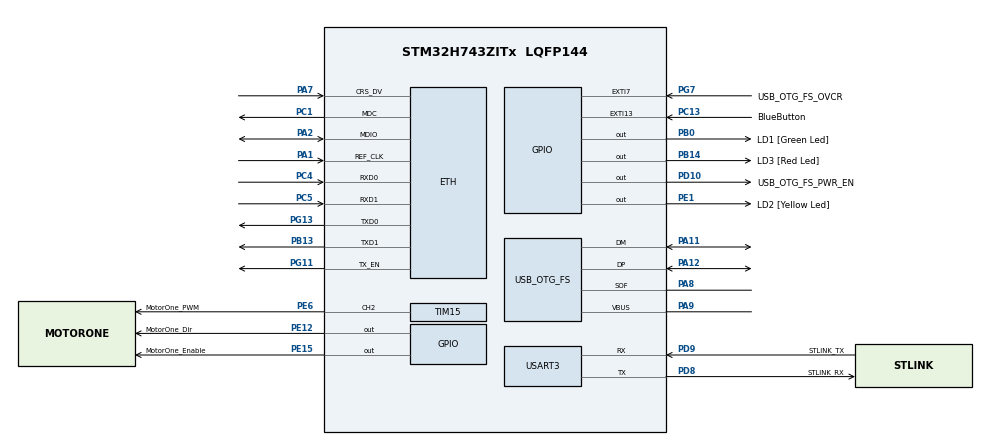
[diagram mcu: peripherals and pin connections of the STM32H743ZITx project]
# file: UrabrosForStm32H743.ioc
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Dma.Request0=USART3_RX
Dma.Request1=USART3_TX
Dma.USART3_RX.0.Direction=DMA_PERIPH_TO_MEMORY
Dma.USART3_RX.0.EventEnable=DISABLE
Dma.USART3_RX.0.FIFOMode=DMA_FIFOMODE_DISABLE
Dma.USART3_RX.0.Instance=DMA1_Stream0
Dma.USART3_RX.0.MemDataAlignment=DMA_MDATAALIGN_BYTE
Dma.USART3_RX.0.MemInc=DMA_MINC_ENABLE
Dma.USART3_RX.0.Mode=DMA_CIRCULAR
Dma.USART3_RX.0.PeriphDataAlignment=DMA_PDATAALIGN_BYTE
Dma.USART3_RX.0.PeriphInc=DMA_PINC_DISABLE
Dma.USART3_RX.0.Polarity=HAL_DMAMUX_REQ_GEN_RISING
Dma.USART3_RX.0.Priority=DMA_PRIORITY_LOW
Dma.USART3_RX.0.RequestNumber=1
Dma.USART3_RX.0.SignalID=NONE
Dma.USART3_RX.0.SyncEnable=DISABLE
Dma.USART3_RX.0.SyncPolarity=HAL_DMAMUX_SYNC_NO_EVENT
Dma.USART3_RX.0.SyncRequestNumber=1
Dma.USART3_RX.0.SyncSignalID=NONE
Dma.USART3_TX.1.Direction=DMA_MEMORY_TO_PERIPH
Dma.USART3_TX.1.EventEnable=DISABLE
Dma.USART3_TX.1.FIFOMode=DMA_FIFOMODE_DISABLE
Dma.USART3_TX.1.Instance=DMA1_Stream1
Dma.USART3_TX.1.MemDataAlignment=DMA_MDATAALIGN_BYTE
Dma.USART3_TX.1.MemInc=DMA_MINC_ENABLE
Dma.USART3_TX.1.Mode=DMA_NORMAL
Dma.USART3_TX.1.PeriphDataAlignment=DMA_PDATAALIGN_BYTE
Dma.USART3_TX.1.PeriphInc=DMA_PINC_DISABLE
Dma.USART3_TX.1.Polarity=HAL_DMAMUX_REQ_GEN_RISING
Dma.USART3_TX.1.Priority=DMA_PRIORITY_LOW
Dma.USART3_TX.1.RequestNumber=1
Dma.USART3_TX.1.SignalID=NONE
Dma.USART3_TX.1.SyncEnable=DISABLE
Dma.USART3_TX.1.SyncPolarity=HAL_DMAMUX_SYNC_NO_EVENT
Dma.USART3_TX.1.SyncRequestNumber=1
Dma.USART3_TX.1.SyncSignalID=NONE
ETH.MediaInterface=HAL_ETH_RMII_MODE
FREERTOS.Tasks01=defaultTask,0,128,StartDefaultTask,Default,NULL,Dynamic,NULL,NULL
Mcu.Family=STM32H7
Mcu.Name=STM32H743ZITx
Mcu.Package=LQFP144
NVIC.DMA1_Stream0_IRQn=true\:5\:0\:false\:false\:true\:true\:false\:true
NVIC.DMA1_Stream1_IRQn=true\:5\:0\:false\:false\:true\:true\:false\:true
NVIC.EXTI15_10_IRQn=true\:5\:0\:false\:false\:true\:true\:true\:true
NVIC.PriorityGroup=NVIC_PRIORITYGROUP_4
NVIC.TIM15_IRQn=true\:5\:0\:false\:false\:true\:true\:true\:true
NVIC.TIM7_IRQn=true\:0\:0\:false\:false\:true\:false\:false\:true
NVIC.TimeBase=TIM7_IRQn
NVIC.TimeBaseIP=TIM7
NVIC.USART3_IRQn=true\:5\:0\:false\:false\:true\:true\:true\:true
PA1.Mode=RMII
PA1.Signal=ETH_REF_CLK
PA11.Mode=Device_Only
PA11.Signal=USB_OTG_FS_DM
PA12.Mode=Device_Only
PA12.Signal=USB_OTG_FS_DP
PA2.Mode=RMII
PA2.Signal=ETH_MDIO
PA7.Mode=RMII
PA7.Signal=ETH_CRS_DV
PA8.Mode=Activate_SOF_FS
PA8.Signal=USB_OTG_FS_SOF
PA9.Mode=Activate_VBUS
PA9.Signal=USB_OTG_FS_VBUS
PB0.GPIO_Label=LD1 [Green Led]
PB0.Signal=GPIO_Output
PB13.Mode=RMII
PB13.Signal=ETH_TXD1
PB14.GPIO_Label=LD3 [Red Led]
PB14.Signal=GPIO_Output
PC1.Mode=RMII
PC1.Signal=ETH_MDC
PC13.GPIO_Label=BlueButton
PC13.Signal=GPXTI13
PC14-OSC32_IN\ (OSC32_IN).Mode=LSE-External-Oscillator
PC14-OSC32_IN\ (OSC32_IN).Signal=RCC_OSC32_IN
PC15-OSC32_OUT\ (OSC32_OUT).Mode=LSE-External-Oscillator
PC15-OSC32_OUT\ (OSC32_OUT).Signal=RCC_OSC32_OUT
PC4.Mode=RMII
PC4.Signal=ETH_RXD0
PC5.Mode=RMII
PC5.Signal=ETH_RXD1
PD10.GPIO_Label=USB_OTG_FS_PWR_EN
PD10.Signal=GPIO_Output
PD8.GPIO_Label=STLINK_RX
PD8.Mode=Asynchronous
PD8.Signal=USART3_TX
PD9.GPIO_Label=STLINK_TX
PD9.Mode=Asynchronous
PD9.Signal=USART3_RX
PE1.GPIO_Label=LD2 [Yellow Led]
PE1.Signal=GPIO_Output
PE12.GPIO_Label=MotorOne_Dir
PE12.Signal=GPIO_Output
PE15.GPIO_Label=MotorOne_Enable
PE15.Signal=GPIO_Output
PE6.GPIO_Label=MotorOne_PWM
PE6.Signal=S_TIM15_CH2
PG11.Mode=RMII
PG11.Signal=ETH_TX_EN
PG13.Mode=RMII
PG13.Signal=ETH_TXD0
PG7.GPIO_Label=USB_OTG_FS_OVCR
PG7.Signal=GPXTI7
PH0-OSC_IN\ (PH0).Mode=HSE-External-Clock-Source
PH0-OSC_IN\ (PH0).Signal=RCC_OSC_IN
PH1-OSC_OUT\ (PH1).Signal=RCC_OSC_OUT
ProjectManager.HeapSize=0x200
ProjectManager.StackSize=0x400
ProjectManager.TargetToolchain=STM32CubeIDE
RCC.ADCFreq_Value=16125000
RCC.APB1Freq_Value=64000000
RCC.APB2Freq_Value=64000000
RCC.APB3Freq_Value=64000000
RCC.APB4Freq_Value=64000000
RCC.CortexFreq_Value=64000000
RCC.DIVM1=1
RCC.DIVN1=24
RCC.DIVQ1=4
RCC.HCLKFreq_Value=64000000
RCC.HSE_VALUE=8000000
RCC.PLL2FRACN=0
RCC.PLL3FRACN=0
RCC.PLLFRACN=0
RCC.SYSCLKFreq_VALUE=64000000
RCC.Tim1Mul=1
RCC.Tim2Mul=1
RCC.USBFreq_Value=48000000
SH.S_TIM15_CH2.0=TIM15_CH2,PWM Generation2 CH2
TIM15.Channel-PWM\ Generation2\ CH2=TIM_CHANNEL_2
USART3.VirtualMode-Asynchronous=VM_ASYNC
USB_OTG_FS.VirtualMode=Device_Only
VP_FREERTOS_VS_CMSIS_V1.Mode=CMSIS_V1
VP_SYS_VS_tim7.Mode=TIM7
board=NUCLEO-H743ZI2

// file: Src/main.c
/* USER CODE BEGIN Header */
/**
  ******************************************************************************
  * @file           : main.c
  * @brief          : Main program body
  ******************************************************************************
  * @attention
  *
  * <h2><center>&copy; Copyright (c) 2020 STMicroelectronics.
  * All rights reserved.</center></h2>
  *
  * This software component is licensed by ST under Ultimate Liberty license
  * SLA0044, the "License"; You may not use this file except in compliance with
  * the License. You may obtain a copy of the License at:
  *                             www.st.com/SLA0044
  *
  ******************************************************************************
  */
/* USER CODE END Header */
#include "main.h"
#include "cmsis_os.h"
#include "dma.h"
#include "eth.h"
#include "tim.h"
#include "usart.h"
#include "usb_otg.h"
#include "gpio.h"
#include "UrabrosMaster.h"

void SystemClock_Config(void);

int main(void)
{

  /* MCU Configuration--------------------------------------------------------*/

  /* Reset of all peripherals, Initializes the Flash interface and the Systick. */
  HAL_Init();

  /* Configure the system clock */
  SystemClock_Config();

  /* Initialize all configured peripherals */
  MX_GPIO_Init();
  MX_DMA_Init();
  MX_ETH_Init();
  MX_USART3_UART_Init();
  MX_USB_OTG_FS_PCD_Init();
  MX_TIM15_Init();
  /* USER CODE BEGIN 2 */
  UrabrosInit();
  /* USER CODE END 2 */

  /* Call init function for freertos objects (in freertos.c) */
  /* Start scheduler */
  osKernelStart();

  /* We should never get here as control is now taken by the scheduler */
  /* Infinite loop */
  while (1)
  {

  }
}

void SystemClock_Config(void)
{
  RCC_OscInitTypeDef RCC_OscInitStruct = {0};
  RCC_ClkInitTypeDef RCC_ClkInitStruct = {0};
  RCC_PeriphCLKInitTypeDef PeriphClkInitStruct = {0};

  /** Supply configuration update enable
  */
  HAL_PWREx_ConfigSupply(PWR_LDO_SUPPLY);
  /** Configure the main internal regulator output voltage
  */
  __HAL_PWR_VOLTAGESCALING_CONFIG(PWR_REGULATOR_VOLTAGE_SCALE3);

  while(!__HAL_PWR_GET_FLAG(PWR_FLAG_VOSRDY)) {}
  /** Initializes the RCC Oscillators according to the specified parameters
  * in the RCC_OscInitTypeDef structure.
  */
  RCC_OscInitStruct.OscillatorType = RCC_OSCILLATORTYPE_HSI|RCC_OSCILLATORTYPE_HSE;
  RCC_OscInitStruct.HSEState = RCC_HSE_BYPASS;
  RCC_OscInitStruct.HSIState = RCC_HSI_DIV1;
  RCC_OscInitStruct.HSICalibrationValue = RCC_HSICALIBRATION_DEFAULT;
  RCC_OscInitStruct.PLL.PLLState = RCC_PLL_ON;
  RCC_OscInitStruct.PLL.PLLSource = RCC_PLLSOURCE_HSE;
  RCC_OscInitStruct.PLL.PLLM = 1;
  RCC_OscInitStruct.PLL.PLLN = 24;
  RCC_OscInitStruct.PLL.PLLP = 2;
  RCC_OscInitStruct.PLL.PLLQ = 4;
  RCC_OscInitStruct.PLL.PLLR = 2;
  RCC_OscInitStruct.PLL.PLLRGE = RCC_PLL1VCIRANGE_3;
  RCC_OscInitStruct.PLL.PLLVCOSEL = RCC_PLL1VCOWIDE;
  RCC_OscInitStruct.PLL.PLLFRACN = 0;
  if (HAL_RCC_OscConfig(&RCC_OscInitStruct) != HAL_OK)
  {
    Error_Handler();
  }
  /** Initializes the CPU, AHB and APB buses clocks
  */
  RCC_ClkInitStruct.ClockType = RCC_CLOCKTYPE_HCLK|RCC_CLOCKTYPE_SYSCLK
                              |RCC_CLOCKTYPE_PCLK1|RCC_CLOCKTYPE_PCLK2
                              |RCC_CLOCKTYPE_D3PCLK1|RCC_CLOCKTYPE_D1PCLK1;
  RCC_ClkInitStruct.SYSCLKSource = RCC_SYSCLKSOURCE_HSI;
  RCC_ClkInitStruct.SYSCLKDivider = RCC_SYSCLK_DIV1;
  RCC_ClkInitStruct.AHBCLKDivider = RCC_HCLK_DIV1;
  RCC_ClkInitStruct.APB3CLKDivider = RCC_APB3_DIV1;
  RCC_ClkInitStruct.APB1CLKDivider = RCC_APB1_DIV1;
  RCC_ClkInitStruct.APB2CLKDivider = RCC_APB2_DIV1;
  RCC_ClkInitStruct.APB4CLKDivider = RCC_APB4_DIV1;

  if (HAL_RCC_ClockConfig(&RCC_ClkInitStruct, FLASH_LATENCY_0) != HAL_OK)
  {
    Error_Handler();
  }
  PeriphClkInitStruct.PeriphClockSelection = RCC_PERIPHCLK_USART3|RCC_PERIPHCLK_USB;
  PeriphClkInitStruct.Usart234578ClockSelection = RCC_USART234578CLKSOURCE_D2PCLK1;
  PeriphClkInitStruct.UsbClockSelection = RCC_USBCLKSOURCE_PLL;
  if (HAL_RCCEx_PeriphCLKConfig(&PeriphClkInitStruct) != HAL_OK)
  {
    Error_Handler();
  }
  /** Enable USB Voltage detector
  */
  HAL_PWREx_EnableUSBVoltageDetector();
}

 /**
  * @brief  Period elapsed callback in non blocking mode
  * @note   This function is called  when TIM7 interrupt took place, inside
  * HAL_TIM_IRQHandler(). It makes a direct call to HAL_IncTick() to increment
  * a global variable "uwTick" used as application time base.
  * @param  htim : TIM handle
  * @retval None
  */
void HAL_TIM_PeriodElapsedCallback(TIM_HandleTypeDef *htim)
{
  if (htim->Instance == TIM7) {
    HAL_IncTick();
  }
}

void Error_Handler(void)
{
}

/************************ (C) COPYRIGHT STMicroelectronics *****END OF FILE****/
